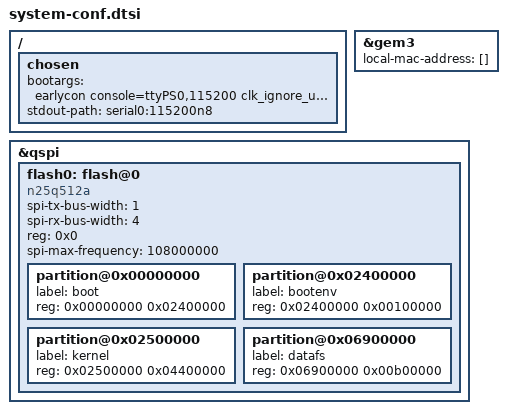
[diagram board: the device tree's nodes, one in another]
/*
 * CAUTION: This file is automatically generated by PetaLinux SDK.
 * DO NOT modify this file
 */


/ {
	chosen {
		bootargs = "earlycon console=ttyPS0,115200 clk_ignore_unused root=/dev/mmcblk0p2 rw rootwait";
		stdout-path = "serial0:115200n8";
	};
};

&gem3 {
	local-mac-address = [];
};

&qspi {
	#address-cells = <1>;
	#size-cells = <0>;
	flash0: flash@0 {
		compatible = "n25q512a","micron,m25p80";
		spi-tx-bus-width=<1>;
		spi-rx-bus-width=<4>;
		reg = <0x0>;
		#address-cells = <1>;
		#size-cells = <1>;
		spi-max-frequency = <108000000>;
		/delete-node/ partition@qspi-fsbl-uboot;
		/delete-node/ partition@qspi-linux;
		/delete-node/ partition@qspi-device-tree;
		/delete-node/ partition@qspi-rootfs;
		/delete-node/ partition@qspi-bitstream;
		partition@0x00000000 {
			label = "boot";
			reg = <0x00000000 0x02400000>;
		};
		partition@0x02400000 {
			label = "bootenv";
			reg = <0x02400000 0x00100000>;
		};
		partition@0x02500000 {
			label = "kernel";
			reg = <0x02500000 0x04400000>;
		};
		partition@0x06900000 {
			label = "datafs";
			reg = <0x06900000 0x00b00000>;
		};
	};
};

